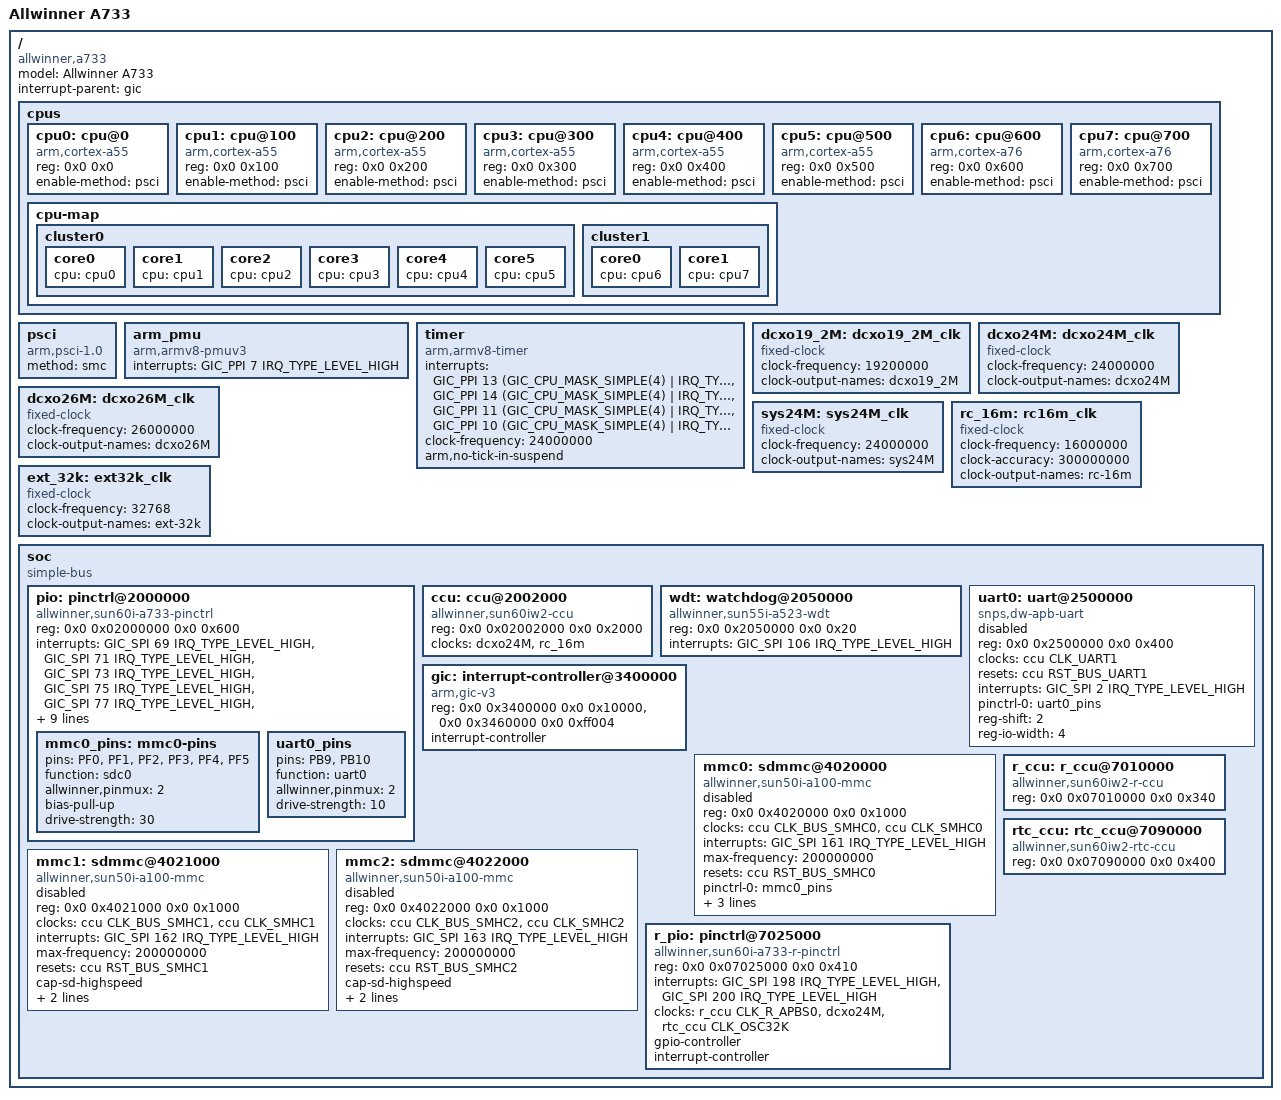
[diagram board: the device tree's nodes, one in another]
// SPDX-License-Identifier: (GPL-2.0-or-later OR MIT)
/*
 * Copyright (C) 2015-2025 Allwinner Technology Co., Ltd.
 * Author: Yao Zi <me@ziyao.cc>
 */

/dts-v1/;

#include <dt-bindings/clock/sun60i-a733-ccu.h>
#include <dt-bindings/clock/sun60i-a733-rtc.h>
#include <dt-bindings/clock/sun60i-a733-r-ccu.h>
#include <dt-bindings/interrupt-controller/arm-gic.h>
#include <dt-bindings/reset/sun60i-a733-ccu.h>

/ {
	compatible = "allwinner,a733";
	model = "Allwinner A733";
	interrupt-parent = <&gic>;
	#address-cells = <2>;
	#size-cells = <2>;

	cpus {
		#address-cells = <2>;
		#size-cells = <0>;

		cpu0: cpu@0 {
			device_type = "cpu";
			compatible = "arm,cortex-a55";
			reg = <0x0 0x0>;
			enable-method = "psci";
		};

		cpu1: cpu@100 {
			device_type = "cpu";
			compatible = "arm,cortex-a55";
			reg = <0x0 0x100>;
			enable-method = "psci";
		};

		cpu2: cpu@200 {
			device_type = "cpu";
			compatible = "arm,cortex-a55";
			reg = <0x0 0x200>;
			enable-method = "psci";
		};

		cpu3: cpu@300 {
			device_type = "cpu";
			compatible = "arm,cortex-a55";
			reg = <0x0 0x300>;
			enable-method = "psci";
		};

		cpu4: cpu@400 {
			device_type = "cpu";
			compatible = "arm,cortex-a55";
			reg = <0x0 0x400>;
			enable-method = "psci";
		};

		cpu5: cpu@500 {
			device_type = "cpu";
			compatible = "arm,cortex-a55";
			reg = <0x0 0x500>;
			enable-method = "psci";
		};

		cpu6: cpu@600 {
			device_type = "cpu";
			compatible = "arm,cortex-a76";
			reg = <0x0 0x600>;
			enable-method = "psci";
		};

		cpu7: cpu@700 {
			device_type = "cpu";
			compatible = "arm,cortex-a76";
			reg = <0x0 0x700>;
			enable-method = "psci";
		};

		cpu-map {
			cluster0 {
				core0 {
					cpu = <&cpu0>;
				};

				core1 {
					cpu = <&cpu1>;
				};

				core2 {
					cpu = <&cpu2>;
				};

				core3 {
					cpu = <&cpu3>;
				};

				core4 {
					cpu = <&cpu4>;
				};

				core5 {
					cpu = <&cpu5>;
				};
			};

			cluster1 {
				core0 {
					cpu = <&cpu6>;
				};

				core1 {
					cpu = <&cpu7>;
				};
			};
		};
	};

	psci {
		compatible = "arm,psci-1.0";
		method = "smc";
	};

	arm_pmu {
		compatible = "arm,armv8-pmuv3";
		interrupts = <GIC_PPI 7 IRQ_TYPE_LEVEL_HIGH>;
	};

	timer {
		compatible = "arm,armv8-timer";
		interrupts = <GIC_PPI 13 (GIC_CPU_MASK_SIMPLE(4) | IRQ_TYPE_LEVEL_LOW)>,
			     <GIC_PPI 14 (GIC_CPU_MASK_SIMPLE(4) | IRQ_TYPE_LEVEL_LOW)>,
			     <GIC_PPI 11 (GIC_CPU_MASK_SIMPLE(4) | IRQ_TYPE_LEVEL_LOW)>,
			     <GIC_PPI 10 (GIC_CPU_MASK_SIMPLE(4) | IRQ_TYPE_LEVEL_LOW)>;
		clock-frequency = <24000000>;
		arm,no-tick-in-suspend;
	};

	dcxo19_2M: dcxo19_2M_clk {
		#clock-cells = <0>;
		compatible = "fixed-clock";
		clock-frequency = <19200000>;
		clock-output-names = "dcxo19_2M";
	};

	dcxo24M: dcxo24M_clk {
		#clock-cells = <0>;
		compatible = "fixed-clock";
		clock-frequency = <24000000>;
		clock-output-names = "dcxo24M";
	};

	dcxo26M: dcxo26M_clk {
		#clock-cells = <0>;
		compatible = "fixed-clock";
		clock-frequency = <26000000>;
		clock-output-names = "dcxo26M";
	};

	sys24M: sys24M_clk {
		#clock-cells = <0>;
		compatible = "fixed-clock";
		clock-frequency = <24000000>;
		clock-output-names = "sys24M";
	};

	rc_16m: rc16m_clk {
		#clock-cells = <0>;
		compatible = "fixed-clock";
		clock-frequency = <16000000>;
		clock-accuracy = <300000000>;
		clock-output-names = "rc-16m";
	};

	ext_32k: ext32k_clk {
		#clock-cells = <0>;
		compatible = "fixed-clock";
		clock-frequency = <32768>;
		clock-output-names = "ext-32k";
	};

	soc {
		compatible = "simple-bus";
		#address-cells = <2>;
		#size-cells = <2>;
		ranges;

		pio: pinctrl@2000000 {
			compatible = "allwinner,sun60i-a733-pinctrl";
			reg = <0x0 0x02000000 0x0 0x600>;
			interrupts = <GIC_SPI 69 IRQ_TYPE_LEVEL_HIGH>,
				     <GIC_SPI 71 IRQ_TYPE_LEVEL_HIGH>,
				     <GIC_SPI 73 IRQ_TYPE_LEVEL_HIGH>,
				     <GIC_SPI 75 IRQ_TYPE_LEVEL_HIGH>,
				     <GIC_SPI 77 IRQ_TYPE_LEVEL_HIGH>,
				     <GIC_SPI 79 IRQ_TYPE_LEVEL_HIGH>,
				     <GIC_SPI 81 IRQ_TYPE_LEVEL_HIGH>,
				     <GIC_SPI 83 IRQ_TYPE_LEVEL_HIGH>,
				     <GIC_SPI 85 IRQ_TYPE_LEVEL_HIGH>,
				     <GIC_SPI 87 IRQ_TYPE_LEVEL_HIGH>;
			clocks = <&ccu CLK_APB1>, <&dcxo24M>, <&rtc_ccu CLK_OSC32K>;
			clock-names = "apb", "hosc", "losc";
			gpio-controller;
			#gpio-cells = <3>;
			interrupt-controller;
			#interrupt-cells = <3>;

			mmc0_pins: mmc0-pins {
				pins = "PF0", "PF1", "PF2", "PF3", "PF4", "PF5";
				function = "sdc0";
				allwinner,pinmux = <2>;
				bias-pull-up;
				drive-strength = <30>;
			};

			uart0_pins: uart0_pins {
				pins = "PB9", "PB10";
				function = "uart0";
				allwinner,pinmux = <2>;
				drive-strength = <10>;
			};
		};

		ccu: ccu@2002000 {
			compatible = "allwinner,sun60iw2-ccu";
			reg = <0x0 0x02002000 0x0 0x2000>;
			clocks = <&dcxo24M>, <&rc_16m>;
			clock-names = "hosc", "iosc";
			#clock-cells = <1>;
			#reset-cells = <1>;
		};

		wdt: watchdog@2050000 {
			compatible = "allwinner,sun55i-a523-wdt";
			reg = <0x0 0x2050000 0x0 0x20>;
			interrupts = <GIC_SPI 106 IRQ_TYPE_LEVEL_HIGH>;
		};

		uart0: uart@2500000 {
			compatible = "snps,dw-apb-uart";
			reg = <0x0 0x2500000 0x0 0x400>;
			clocks = <&ccu CLK_UART1>;
			resets = <&ccu RST_BUS_UART1>;
			interrupts = <GIC_SPI 2 IRQ_TYPE_LEVEL_HIGH>;
			pinctrl-names = "default";
			pinctrl-0 = <&uart0_pins>;
			reg-shift = <2>;
			reg-io-width = <4>;
			status = "disabled";
		};

		gic: interrupt-controller@3400000 {
			compatible = "arm,gic-v3";
			reg = <0x0 0x3400000 0x0 0x10000>,
			      <0x0 0x3460000 0x0 0xff004>;
			interrupt-controller;
			#interrupt-cells = <3>;
			#address-cells = <0>;
		};

		mmc0: sdmmc@4020000 {
			compatible = "allwinner,sun50i-a100-mmc";
			reg = <0x0 0x4020000 0x0 0x1000>;
			clocks = <&ccu CLK_BUS_SMHC0>, <&ccu CLK_SMHC0>;
			clock-names = "ahb", "mmc";
			interrupts = <GIC_SPI 161 IRQ_TYPE_LEVEL_HIGH>;
			max-frequency = <200000000>;
			resets = <&ccu RST_BUS_SMHC0>;
			reset-names = "ahb";
			pinctrl-names = "default";
			pinctrl-0 = <&mmc0_pins>;
			status = "disabled";

			cap-sd-highspeed;
			cap-mmc-highspeed;
			cap-sdio-irq;
			#address-cells = <1>;
			#size-cells = <0>;
		};

		mmc1: sdmmc@4021000 {
			compatible = "allwinner,sun50i-a100-mmc";
			reg = <0x0 0x4021000 0x0 0x1000>;
			clocks = <&ccu CLK_BUS_SMHC1>, <&ccu CLK_SMHC1>;
			clock-names = "ahb", "mmc";
			interrupts = <GIC_SPI 162 IRQ_TYPE_LEVEL_HIGH>;
			max-frequency = <200000000>;
			resets = <&ccu RST_BUS_SMHC1>;
			reset-names = "ahb";
			status = "disabled";

			cap-sd-highspeed;
			cap-mmc-highspeed;
			cap-sdio-irq;
			#address-cells = <1>;
			#size-cells = <0>;
		};

		mmc2: sdmmc@4022000 {
			compatible = "allwinner,sun50i-a100-mmc";
			reg = <0x0 0x4022000 0x0 0x1000>;
			clocks = <&ccu CLK_BUS_SMHC2>, <&ccu CLK_SMHC2>;
			clock-names = "ahb", "mmc";
			interrupts = <GIC_SPI 163 IRQ_TYPE_LEVEL_HIGH>;
			max-frequency = <200000000>;
			resets = <&ccu RST_BUS_SMHC2>;
			reset-names = "ahb";
			status = "disabled";

			cap-sd-highspeed;
			cap-mmc-highspeed;
			cap-sdio-irq;
			#address-cells = <1>;
			#size-cells = <0>;
		};

		r_ccu: r_ccu@7010000 {
			compatible = "allwinner,sun60iw2-r-ccu";
			reg = <0x0 0x07010000 0x0 0x340>;
			#clock-cells = <1>;
			#reset-cells = <1>;
		};

		r_pio: pinctrl@7025000 {
			compatible = "allwinner,sun60i-a733-r-pinctrl";
			reg = <0x0 0x07025000 0x0 0x410>;
			interrupts = <GIC_SPI 198 IRQ_TYPE_LEVEL_HIGH>,
				     <GIC_SPI 200 IRQ_TYPE_LEVEL_HIGH>;
			clocks = <&r_ccu CLK_R_APBS0>, <&dcxo24M>, <&rtc_ccu CLK_OSC32K>;
			clock-names = "apb", "hosc", "losc";
			gpio-controller;
			#gpio-cells = <4>;
			interrupt-controller;
			#interrupt-cells = <3>;
		};

		rtc_ccu: rtc_ccu@7090000 {
			compatible = "allwinner,sun60iw2-rtc-ccu";
			reg = <0x0 0x07090000 0x0 0x400>;
			#clock-cells = <1>;
			#reset-cells = <1>;
		};
	};
};
